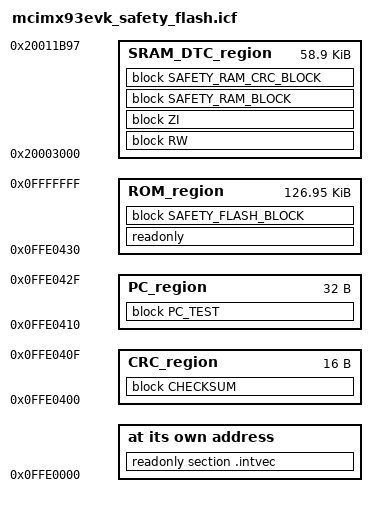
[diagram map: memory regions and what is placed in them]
/*
** ###################################################################
**     Processors:          MIMX9352AVTXM_cm33
**                          MIMX9352CVVXM_cm33
**                          MIMX9352DVVXM_cm33
**                          MIMX9352XVVXM_cm33
**
**     Compiler:            IAR ANSI C/C++ Compiler for ARM
**
**     Abstract:
**         Linker file for the IAR ANSI C/C++ Compiler for ARM
**
**
**     Copyright 2023 NXP.
**     All rights reserved.
**
**     SPDX-License-Identifier: BSD-3-Clause
**
**
**     http:                 www.nxp.com
**     mail:                 support@nxp.com
**
** ###################################################################
*/

/******************************************************************************/
/******************     USER CONFIGURATION PART     ***************************/
/******************************************************************************/
define exported symbol stack_test_block_size = 0x10;
define exported symbol ram_test_backup_size  = 0x20;
define symbol __vector_table_size__          = 0x400;
define symbol __size_cstack__                = 0x0400;

define symbol SRAM_DTC_start       = 0x20003000; /* Part of on-chip RAM (Data-Tightly-Coupled) */
define symbol SRAM_DTC_end         = 0x20011FFF;

define symbol ROM_interrupts_start = 0x0FFE0000; /* IVT in ROM */
define symbol ROM_interrupts_end   = ROM_interrupts_start + __vector_table_size__;

define symbol __FlashCRC_start__   = 0x0FFE0400; /* Place checksum result after IVT (in ROM) */
define symbol __FlashCRC_end__     = 0x0FFE040F;

define symbol __PC_test_start__    = 0x0FFE0410; /* PC object address (pattern to PC:0x30002411) */
define symbol __PC_test_end__      = 0x0FFE042F; /* PC object reserved size: 0x20 */ 

define symbol ROM_start            = 0x0FFE0430; /* ROM memory (external ROM) */
define symbol ROM_end              = 0x0FFFFFFF;

define exported symbol __VECTOR_TABLE = ROM_interrupts_start;

/******************************************************************************/
/******************     SYMBOLS     *******************************************/
/******************************************************************************/ 
define exported symbol m_ram_test_backup    = SRAM_DTC_end - ram_test_backup_size + 0x1;
define exported symbol m_wd_test_backup     = m_ram_test_backup - 0x20;
define exported symbol m_pc_test_flag       = m_wd_test_backup - 0x4;
define exported symbol m_safety_error_code  = m_pc_test_flag - 0x4;
define exported symbol m_stack_test_p_4     = m_safety_error_code - 0x4;
define exported symbol m_stack_test_p_3     = m_stack_test_p_4 - stack_test_block_size +0x4;
define exported symbol __BOOT_STACK_ADDRESS = m_stack_test_p_3 - 0x4;
define exported symbol m_stack_test_p_2     = __BOOT_STACK_ADDRESS - __size_cstack__;
define exported symbol m_stack_test_p_1     = m_stack_test_p_2 - stack_test_block_size + 0x4;
define symbol SRAM_DTC_end_edited           = m_stack_test_p_1 - 0x1;

/******************************************************************************/
/******************     REGIONS     *******************************************/
/******************************************************************************/
define memory mem with size   = 4G;
define region SRAM_DTC_region = mem:[from SRAM_DTC_start to SRAM_DTC_end_edited];
define region CRC_region      = mem:[from __FlashCRC_start__  to __FlashCRC_end__];
define region PC_region       = mem:[from __PC_test_start__ to __PC_test_end__];
define region ROM_region      = mem:[from ROM_start to ROM_end];

/******************************************************************************/
/******************     SECTIONS & BLOCKS    **********************************/
/******************************************************************************/
initialize manually           { readwrite };
initialize manually           { section .data };
initialize manually           { section .bss };
initialize manually           { section .textrw };
initialize manually           { section .safety_ram };
initialize manually           { section .safety_ram_crc };
do not initialize             { section .noinit };

define block RW               { readwrite };
define block ZI               { zi };
define block PC_TEST          { section .text object iec60730b_cm33_pc_object.o };
define block CHECKSUM         { section .checksum };
define block SAFETY_RAM_BLOCK { section .safety_ram };
define block SAFETY_RAM_CRC_BLOCK { section .safety_ram_crc };
define block SAFETY_FLASH_BLOCK with fixed order
{
 readonly section checksum_start_mark,
 section .text         object  main.o,
 section .text         object  safety_cm33_imxrt.o,
 section .rodata       object  safety_cm33_imxrt.o,
 readonly section checksum_end_mark
};

/*****************************************************/
/******************     PLACING     ******************/
/*****************************************************/
place at address mem:ROM_interrupts_start { readonly section .intvec };

place in ROM_region      { readonly };
place in ROM_region      { block SAFETY_FLASH_BLOCK};
place in CRC_region      { block CHECKSUM };
place in PC_region       { block PC_TEST};
place in SRAM_DTC_region { block RW, block ZI };
place in SRAM_DTC_region { block SAFETY_RAM_BLOCK };
place in SRAM_DTC_region { block SAFETY_RAM_CRC_BLOCK };
